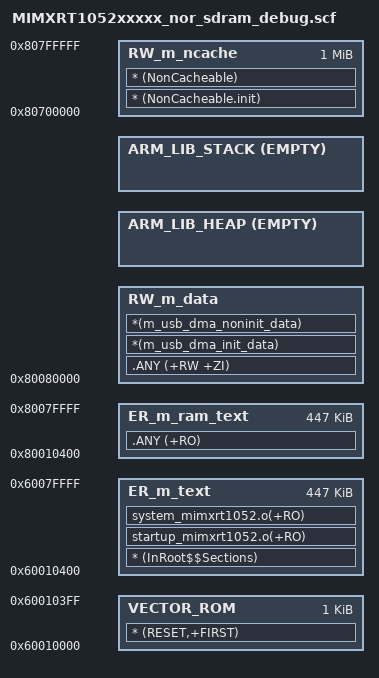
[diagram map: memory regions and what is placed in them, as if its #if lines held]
#! armcc -E
/*
** ###################################################################
**     Processors:          MIMXRT1052CVL5B
**                          MIMXRT1052DVL6B
**
**     Compiler:            Keil ARM C/C++ Compiler
**     Reference manual:    IMXRT1050RM Rev.1, 03/2018
**     Version:             rev. 0.1, 2017-01-10
**     Build:               b180131
**
**     Abstract:
**         Linker file for the Keil ARM C/C++ Compiler
**
**     The Clear BSD License
**     Copyright 2016 Freescale Semiconductor, Inc.
**     Copyright 2016-2018 NXP
**     All rights reserved.
**
**     Redistribution and use in source and binary forms, with or without
**     modification, are permitted (subject to the limitations in the
**     disclaimer below) provided that the following conditions are met:
**
**     * Redistributions of source code must retain the above copyright
**       notice, this list of conditions and the following disclaimer.
**
**     * Redistributions in binary form must reproduce the above copyright
**       notice, this list of conditions and the following disclaimer in the
**       documentation and/or other materials provided with the distribution.
**
**     * Neither the name of the copyright holder nor the names of its
**     GRANTED BY THIS LICENSE. THIS SOFTWARE IS PROVIDED BY THE COPYRIGHT
**     HOLDERS AND CONTRIBUTORS "AS IS" AND ANY EXPRESS OR IMPLIED
**       contributors may be used to endorse or promote products derived from
**       this software without specific prior written permission.
**
**     NO EXPRESS OR IMPLIED LICENSES TO ANY PARTY'S PATENT RIGHTS ARE
**     WARRANTIES, INCLUDING, BUT NOT LIMITED TO, THE IMPLIED WARRANTIES OF
**     MERCHANTABILITY AND FITNESS FOR A PARTICULAR PURPOSE ARE
**     DISCLAIMED. IN NO EVENT SHALL THE COPYRIGHT HOLDER OR CONTRIBUTORS BE
**     LIABLE FOR ANY DIRECT, INDIRECT, INCIDENTAL, SPECIAL, EXEMPLARY, OR
**     CONSEQUENTIAL DAMAGES (INCLUDING, BUT NOT LIMITED TO, PROCUREMENT OF
**     SUBSTITUTE GOODS OR SERVICES; LOSS OF USE, DATA, OR PROFITS; OR
**     BUSINESS INTERRUPTION) HOWEVER CAUSED AND ON ANY THEORY OF LIABILITY,
**     WHETHER IN CONTRACT, STRICT LIABILITY, OR TORT (INCLUDING NEGLIGENCE
**     OR OTHERWISE) ARISING IN ANY WAY OUT OF THE USE OF THIS SOFTWARE, EVEN
**     IF ADVISED OF THE POSSIBILITY OF SUCH DAMAGE.
**
**     http:                 www.nxp.com
**     mail:                 support@nxp.com
**
** ###################################################################
*/
;0x60010000 - 0x60010400 保存的是中断向量表
;0x60010400 - 0x60080000 保存的是代码
;0x60080000 - 0x60080400 保存的是升级参数
;0x60080400 - 0x600F0000 保存的是升级代码
;0x60100000 - 0x60100400 用于管理ADC数据
;其余 用于保存A采样数据
#define m_interrupts_start             0x60010000
#define m_interrupts_size              0x00000400

#define m_text_start                   0x60010400
#define m_text_size                    0x0006FC00

;0x80000000 - 0x8000F000 保存的是boot程序  (60k)
;0x8000F000 - 0x80010000 需要断电保存的参数(4k)
;0x80010000 - 0x80010400 保存的是中断向量表(1k)
;0x80010400 - 0x80042000 保存的是app代码   (199k - 0x31C00)
;0x80042000 - 0x800BF000 保存的是全局变量  (500k - 0x7D000)
;0x800BF000 - 0x80100000 保存的是堆栈以及NonCacheable(500k - 0x7D000)
;;在SDRAM中存放代码的空间
;;中断向量表(1k空间)
#define m_sdram_interrupts_start       0x80010000
#define m_sdram_interrupts_size        0x00000400

;SDRAM中的主体代码(443k)
#define m_sdram_text_start             0x80010400
#define m_sdram_text_size              0x0006FC00

;RW-data与ZI-data空间(6656k)
#define m_data_start                   0x80080000
#define m_data_size                    0x00680000

;ncache(1024k)
#define m_ncache_start                 0x80700000
#define m_ncache_size                  0x00100000



/* Sizes */
#if (defined(__stack_size__))
  #define Stack_Size                   __stack_size__
#else
  #define Stack_Size                   0x2000
#endif

#if (defined(__heap_size__))
  #define Heap_Size                    __heap_size__
#else
#define Heap_Size                    0x200000
#endif


LR_m_text m_interrupts_start m_text_start+m_text_size-m_interrupts_size {   ; load region size_region
  
  ; 在FALSH中的中断向量表
  VECTOR_ROM m_interrupts_start m_interrupts_size { ; load address = execution address
    * (RESET,+FIRST)
  }
  
  ; * (InRoot$$Sections)是__main中从加载域复制代码到执行域的程序scatter_copy，
  ; 启动时运行的startup_mimxrt1052t和system_mimxrt1052中的代码要存放在FLASH中
  ER_m_text m_text_start m_text_size { ; load address = execution address
    * (InRoot$$Sections)
	startup_mimxrt1052.o(+RO)
	system_mimxrt1052.o(+RO)
  }

  ;存放主体程序的SDRAM空间，由__main函数从FLASH中加载
  ER_m_ram_text m_sdram_text_start m_sdram_text_size { ;execution address
    .ANY (+RO)
  }  
  
  RW_m_data m_data_start m_data_size-Stack_Size-Heap_Size { ; RW data
    .ANY (+RW +ZI)
    *(m_usb_dma_init_data)
    *(m_usb_dma_noninit_data)
  }
  ARM_LIB_HEAP +0 EMPTY Heap_Size {    ; Heap region growing up
  }
  ARM_LIB_STACK m_data_start+m_data_size EMPTY -Stack_Size { ; Stack region growing down
  }
  RW_m_ncache m_ncache_start m_ncache_size { ; ncache RW data
    * (NonCacheable.init)
    * (NonCacheable)
  }
}

